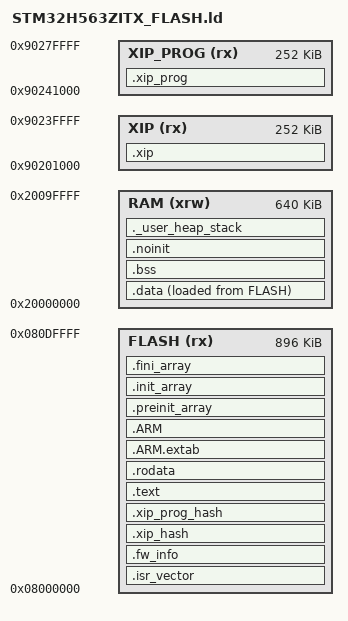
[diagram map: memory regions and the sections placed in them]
/*
******************************************************************************
**
** @file        : LinkerScript.ld
**
** @author      : Auto-generated by STM32CubeIDE
**
** @brief       : Linker script for STM32H563ZITx Device from STM32H5 series
**                      2048Kbytes FLASH
**                      640Kbytes RAM
**
**                Set heap size, stack size and stack location according
**                to application requirements.
**
**                Set memory bank area and size if external memory is used
**
**  Target      : STMicroelectronics STM32
**
**  Distribution: The file is distributed as is, without any warranty
**                of any kind.
**
******************************************************************************
** @attention
**
** Copyright (c) 2021 STMicroelectronics.
** All rights reserved.
**
** This software is licensed under terms that can be found in the LICENSE file
** in the root directory of this software component.
** If no LICENSE file comes with this software, it is provided AS-IS.
**
******************************************************************************
*/

/* Entry Point */
ENTRY(Reset_Handler)

/* Highest address of the user mode stack */
_estack = ORIGIN(RAM) + LENGTH(RAM); /* end of "RAM" Ram type memory */

_Min_Heap_Size = 0x200; /* required amount of heap */
_Min_Stack_Size = 0x400; /* required amount of stack */

/* Memories definition */
/* One image for the 2 MB H563 (ZIT6) and the 1 MB one (ZGT6): the code may use the 1 MB part's
 * flash up to its persistence sectors, 0x080E0000 (896 KB; 928 KB before the pod policy record
 * took two sectors below the others, 912 KB before the LAN TLS certificate took two more), so the same binary fits both and the link
 * fails with "region FLASH overflowed" before it could grow into them.  The persistence records
 * (LAN TLS certificate, pod policy, ADC calibration, DAC limits, OTA self-test scratch, cloud and Wi-Fi config, device identity)
 * sit in the top 128 KB of whichever flash the chip has (src/flash_layout.h); on a 2 MB part the
 * flash between 0x080E0000 and those records is unused.  The ESP32-C3 image and the iCE40
 * gateware live in the W25Q (src/blob_store.h), not here. */
MEMORY
{
  RAM         (xrw)   : ORIGIN = 0x20000000,   LENGTH = 640K
  FLASH       (rx)    : ORIGIN = 0x08000000,   LENGTH = 896K
  /* Code that runs straight from the W25Q (src/xip_image.h): the "xip" blob slot's data, W25Q
     0x201000 to 0x240000, memory-mapped through OCTOSPI1 at 0x90000000. Not in the firmware .bin:
     tools/xip_finish.py writes it to build/blobs/blob-xip.bin. */
  XIP         (rx)    : ORIGIN = 0x90201000,   LENGTH = 252K
  /* The second image (src/xip_image.h): the pin programmers, slot "xip_prog", W25Q 0x240000 */
  XIP_PROG    (rx)    : ORIGIN = 0x90241000,   LENGTH = 252K
}

/* main.c icache_init() makes 0x080E0000 and up non-cacheable (the persistence records and
   bank 2 are written at run time). It must start exactly where the code region ends. */
ASSERT(ORIGIN(FLASH) + LENGTH(FLASH) == 0x080E0000, "FLASH end moved: update the non-cacheable MPU region in main.c icache_init()")

/* Sections */
SECTIONS
{
  /* The startup code into "FLASH" Rom type memory */
  .isr_vector :
  {
    . = ALIGN(4);
    KEEP(*(.isr_vector)) /* Startup code */
    . = ALIGN(4);
  } >FLASH

  /* The image's fw_info block (src/fw_info.h) at a fixed offset right after the vector table,
     where installers look for it. Must match FW_INFO_OFFSET. */
  .fw_info (ORIGIN(FLASH) + 0x400) :
  {
    KEEP(*(.fw_info))
  } >FLASH
  ASSERT(SIZEOF(.isr_vector) <= 0x400, "vector table grew into the fw_info block")
  ASSERT(SIZEOF(.fw_info) == 16, "fw_info block missing or resized")

  /* The program code and other data into "FLASH" Rom type memory */
  /* The W25Q image (src/xip_image.h): the table first, then every src/xip_mod_*.c object's code
     and constants. Their .data/.bss would land in RAM below; tools/check_xip_refs.py forbids them. */
  .xip :
  {
    __xip_start = .;
    KEEP(*(.xip.table))
    *xip_mod_*.o(.text .text* .rodata .rodata*)
    *(.xip.text*)
    *(.xip.rodata*)
    . = ALIGN(4);
    __xip_end = .;
  } >XIP
  __xip_region_end = ORIGIN(XIP) + LENGTH(XIP);

  /* The second W25Q image: the table first, then the pin programmers (prog_flash) and xip_prog_mod.c.
     Memory-mapped builds link it at its own W25Q address. A RAM build (XIP_RAM=1) replaces the XIP
     and XIP_PROG lines above with the adc_pool's RAM region, up to 64 KB (the Makefile): the two
     images overlay each other and the pool there, which is why AT() gives this one a load address of its own, the one the
     mapped build uses (the linker refuses two sections with the same load address). The image is
     extracted by section name (tools/xip_finish.py), so the load address is not used. */
  .xip_prog : AT(0x90241000)
  {
    __xip_prog_start = .;
    KEEP(*(.xip_prog.table))
    *xip_prog_mod.o(.text .text* .rodata .rodata*)
    *prog_updi.o(.text .text* .rodata .rodata*)
    *prog_pic.o(.text .text* .rodata .rodata*)
    *prog_c2.o(.text .text* .rodata .rodata*)
    *prog_tpi.o(.text .text* .rodata .rodata*)
    *prog_pdi.o(.text .text* .rodata .rodata*)
    *prog_sbw.o(.text .text* .rodata .rodata*)
    *sensor_def_compile.o(.text .text* .rodata .rodata*)   /* XIP_PROG_SENSOR_COMPILE (the EMC test build drops these two lines) */
    *sensor_def_expr.o(.text .text* .rodata .rodata*)      /* XIP_PROG_SENSOR_COMPILE */
    . = ALIGN(4);
    __xip_prog_end = .;
  } >XIP_PROG
  __xip_prog_region_end = ORIGIN(XIP_PROG) + LENGTH(XIP_PROG);

  /* XIP_RAM=1 builds (the Makefile fills this in): adc_pool (src/adc_pool.h) at its own fixed
     region, the end of RAM, and both W25Q images linked at that same address (the XIP and
     XIP_PROG regions above): a session copies its image over the idle pool. */
  /* ADC_POOL_SECTION */

  /* What the post-link step found in .xip (src/xip_image.c, patched by tools/xip_finish.py). */
  .xip_hash :
  {
    . = ALIGN(4);
    KEEP(*(.xip_hash))
  } >FLASH
  .xip_prog_hash :
  {
    . = ALIGN(4);
    KEEP(*(.xip_prog_hash))
  } >FLASH

  .text :
  {
    . = ALIGN(4);
    *(.text)           /* .text sections (code) */
    *(.text*)          /* .text* sections (code) */
    *(.glue_7)         /* glue arm to thumb code */
    *(.glue_7t)        /* glue thumb to arm code */
    *(.eh_frame)

    KEEP (*(.init))
    KEEP (*(.fini))

    . = ALIGN(4);
    _etext = .;        /* define a global symbols at end of code */
  } >FLASH

  /* Constant data into "FLASH" Rom type memory */
  .rodata :
  {
    . = ALIGN(4);
    *(.rodata)         /* .rodata sections (constants, strings, etc.) */
    *(.rodata*)        /* .rodata* sections (constants, strings, etc.) */
    . = ALIGN(4);
  } >FLASH

  .ARM.extab (READONLY) : /* The READONLY keyword is only supported in GCC11 and later, remove it if using GCC10 or earlier. */
  {
    . = ALIGN(4);
    *(.ARM.extab* .gnu.linkonce.armextab.*)
    . = ALIGN(4);
  } >FLASH

  .ARM (READONLY) : /* The READONLY keyword is only supported in GCC11 and later, remove it if using GCC10 or earlier. */
  {
    . = ALIGN(4);
    __exidx_start = .;
    *(.ARM.exidx*)
    __exidx_end = .;
    . = ALIGN(4);
  } >FLASH

  .preinit_array (READONLY) : /* The READONLY keyword is only supported in GCC11 and later, remove it if using GCC10 or earlier. */
  {
    . = ALIGN(4);
    PROVIDE_HIDDEN (__preinit_array_start = .);
    KEEP (*(.preinit_array*))
    PROVIDE_HIDDEN (__preinit_array_end = .);
    . = ALIGN(4);
  } >FLASH

  .init_array (READONLY) : /* The READONLY keyword is only supported in GCC11 and later, remove it if using GCC10 or earlier. */
  {
    . = ALIGN(4);
    PROVIDE_HIDDEN (__init_array_start = .);
    KEEP (*(SORT(.init_array.*)))
    KEEP (*(.init_array*))
    PROVIDE_HIDDEN (__init_array_end = .);
    . = ALIGN(4);
  } >FLASH

  .fini_array (READONLY) : /* The READONLY keyword is only supported in GCC11 and later, remove it if using GCC10 or earlier. */
  {
    . = ALIGN(4);
    PROVIDE_HIDDEN (__fini_array_start = .);
    KEEP (*(SORT(.fini_array.*)))
    KEEP (*(.fini_array*))
    PROVIDE_HIDDEN (__fini_array_end = .);
    . = ALIGN(4);
  } >FLASH

  /* Used by the startup to initialize data */
  _sidata = LOADADDR(.data);

  /* Initialized data sections into "RAM" Ram type memory */
  .data :
  {
    . = ALIGN(4);
    _sdata = .;        /* create a global symbol at data start */
    *(.data)           /* .data sections */
    *(.data*)          /* .data* sections */
    *(.RamFunc)        /* .RamFunc sections */
    *(.RamFunc*)       /* .RamFunc* sections */

    . = ALIGN(4);
    _edata = .;        /* define a global symbol at data end */

  } >RAM AT> FLASH

  /* Uninitialized data section into "RAM" Ram type memory */
  . = ALIGN(4);
  .bss :
  {
    /* This is used by the startup in order to initialize the .bss section */
    _sbss = .;         /* define a global symbol at bss start */
    __bss_start__ = _sbss;
    *(.bss)
    *(.bss*)
    *(COMMON)

    . = ALIGN(4);
    _ebss = .;         /* define a global symbol at bss end */
    __bss_end__ = _ebss;
  } >RAM

  /* No-init RAM: not loaded from flash, not zeroed by startup, so its contents
     survive a warm reset (NVIC_SystemReset).  Used by dfu_boot.c to carry the
     "reboot into DFU bootloader" flag across the reset. */
  .noinit (NOLOAD) :
  {
    . = ALIGN(4);
    _snoinit = .;
    *(.noinit)
    *(.noinit*)
    . = ALIGN(4);
    _enoinit = .;
  } >RAM

  /* User_heap_stack section, used to check that there is enough "RAM" Ram  type memory left */
  ._user_heap_stack :
  {
    . = ALIGN(8);
    PROVIDE ( end = . );
    PROVIDE ( _end = . );
    . = . + _Min_Heap_Size;
    . = . + _Min_Stack_Size;
    . = ALIGN(8);
  } >RAM

  /* Remove information from the compiler libraries */
  /DISCARD/ :
  {
    libc.a ( * )
    libm.a ( * )
    libgcc.a ( * )
  }

  .ARM.attributes 0 : { *(.ARM.attributes) }
}
